# STM32H743 register map
File version: 2.4
CPU: CM7 r0p1, little endian, MPU, FPU, 4 interrupt priority bits
Registers are 32-bit, read-write, reset 0x0 unless marked. A register's access mark holds for its fields unless they carry their own. Offsets are from the block's base; [hi:lo] are bit positions.

## CEC — HDMI-CEC 控制器
Base 0x40006C00
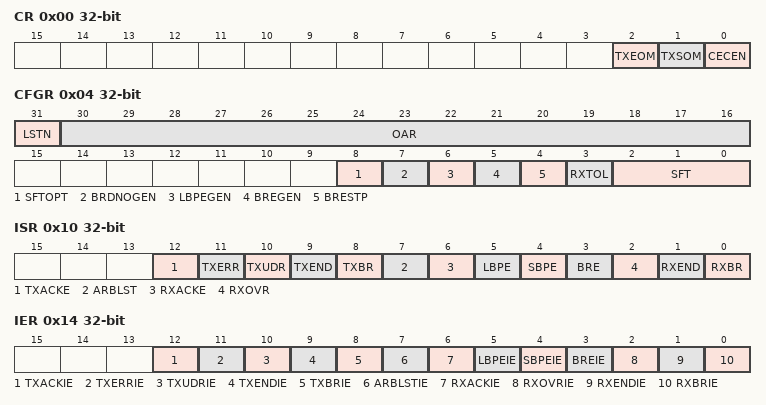
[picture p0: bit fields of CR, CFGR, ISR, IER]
0x00 CR — CEC 控制寄存器
  [2] TXEOM — 发送消息结束 TXEOM 由软件置位，用于命令发送 CEC 消息的最后一个字节。TXEOM 在与 TXSOM 相同的时间和条件下由硬件清零。注意：TXEOM 必须在 CECEN=1 时置位；TXEOM 必须在向 TXDR 写入发送数据之前置位；若 TXEOM 在 TXSOM=0 时置位，发送的消息将仅包含 1 个字节（HEADER）（即 PING 消息）。
  [1] TXSOM — 发送消息起始 TXSOM 由软件置位，用于命令发送 CEC 消息的第一个字节。如果 CEC 消息仅包含一个字节，则 TXEOM 必须在 TXSOM 之前置位。起始位在 SFT 计数完成后于 CEC 线上实际开始。如果在消息接收进行中置位 TXSOM，发送将在接收结束后开始。TXSOM 在消息最后一个字节发送成功并收到正应答后（TXEND=1）、发生发送欠载（TXUDR=1）、收到负应答（TXACKE=1）以及发送错误（TXERR=1）时由硬件清零。CECEN=0 也会将其清零。在仲裁丢失（ARBLST=1）的情况下，TXSOM 不会被清零，发送将自动重试。TXSOM 也可作为状态位，用于通知应用程序当前是否有发送请求等待处理或正在执行。应用程序可随时通过清零 CECEN 位来中止发送请求。注意：TXSOM 必须在 CECEN=1 时置位；TXSOM 必须在 TXDR 中有发送数据可用时置位；HEADER 的前四位（包含本机外设地址）取自 TXDR[7:4]，而非 CEC_CFGR.OAR，后者仅用于接收。
  [0] CECEN — CEC 使能 CECEN 位由软件置位和清零。CECEN=1 启动消息接收并使能 TXSOM 控制。CECEN=0 禁用 CEC 外设，清零 CEC_CR 寄存器的所有位，并中止任何正在进行的接收或发送。
0x04 CFGR — 此寄存器用于配置 HDMI-CEC 控制器。必须仅在 CECEN=0 时才能写 CEC_CFGR。
  [31] LSTN — 侦听模式 LSTN 位由软件置位和清零。
  [30:16] OAR — 本机地址配置 OAR 位由软件置位，用于选择在接收模式下需要考虑的目标逻辑地址。每个位置位时，使能由该位位置标识的 CEC 逻辑地址。HEADER 接收结束时，将收到的目标地址与已使能的地址进行比较。若地址匹配，则应答并接收传入消息。若地址不匹配，则仅在侦听模式（LSTN=1）下接收传入消息，但不发送应答。广播消息始终被接收。示例：OAR = 0b000 0000 0010 0001 表示 CEC 应答地址 0x0 和 0x5。因此，发往这两个地址中任意一个的每条消息均会被接收。
  [8] SFTOPT — SFT 选项位 SFTOPT 位由软件置位和清零。
  [7] BRDNOGEN — 禁止广播中生成错误位 BRDNOGEN 位由软件置位和清零。
  [6] LBPEGEN — 长位周期错误时生成错误位 LBPEGEN 位由软件置位和清零。注意：若 BRDNOGEN=0，在广播中检测到 LBPE 时，即使 LBPEGEN=0 也会生成错误位。
  [5] BREGEN — 位上升沿错误时生成错误位 BREGEN 位由软件置位和清零。注意：若 BRDNOGEN=0，在广播中检测到 BRE 且 BRESTP=1 时，即使 BREGEN=0 也会生成错误位。
  [4] BRESTP — 位上升沿错误时停止接收 BRESTP 位由软件置位和清零。
  [3] RXTOL — 接收容差 RXTOL 位由软件置位和清零。** 标准容差：起始位上升沿 +/- 200μs，下降沿 +/- 200μs；数据位上升沿 +/- 200μs，下降沿 +/- 350μs。** 扩展容差：起始位上升沿 +/- 400μs，下降沿 +/- 400μs；数据位上升沿 +/- 300μs，下降沿 +/- 500μs。
  [2:0] SFT — 信号空闲时间 SFT 位由软件置位。在 SFT=0x0 配置下，发送前等待的标称数据位周期数由硬件根据发送历史决定。在所有其他配置下，SFT 数值由软件确定。* 0x0：** 若 CEC 是上次总线发起者且发送不成功（ARBLST=1、TXERR=1、TXUDR=1 或 TXACKE=1），则等待 2.5 个数据位周期；** 若 CEC 是新的总线发起者，则等待 4 个数据位周期；** 若 CEC 是上次总线发起者且发送成功（TXEOM=1），则等待 6 个数据位周期；* 0x1：0.5 个标称数据位周期 * 0x2：1.5 个标称数据位周期 * 0x3：2.5 个标称数据位周期 * 0x4：3.5 个标称数据位周期 * 0x5：4.5 个标称数据位周期 * 0x6：5.5 个标称数据位周期 * 0x7：6.5 个标称数据位周期
0x08 TXDR wo — CEC 发送数据寄存器
  [7:0] TXD — 发送数据寄存器。TXD 为只写寄存器，包含待发送的数据字节。注意：TXD 必须在 TXSTART=1 时写入。
0x0C RXDR ro — CEC 接收数据寄存器
  [7:0] RXD — 接收数据寄存器。RXD 为只读寄存器，包含从 CEC 线上收到的最后一个数据字节。
0x10 ISR — CEC 中断和状态寄存器
  [12] TXACKE — 发送应答丢失错误 在发送模式下，TXACKE 由硬件置位，用于通知应用程序未收到应答。在广播发送情况下，TXACKE 通知应用程序收到了负应答。TXACKE 中止消息发送并清零 TXSOM 和 TXEOM 控制位。TXACKE 由软件写 1 清零。
  [11] TXERR — 发送错误 在发送模式下，若 CEC 发起者在释放 CEC 线时检测到低阻抗，TXERR 由硬件置位。TXERR 中止消息发送并清零 TXSOM 和 TXEOM 控制位。TXERR 由软件写 1 清零。
  [10] TXUDR — 发送缓冲区欠载 在发送模式下，若应用程序未能在下一字节发送前及时加载 TXDR，TXUDR 由硬件置位。TXUDR 中止消息发送并清零 TXSOM 和 TXEOM 控制位。TXUDR 由软件写 1 清零。
  [9] TXEND — 发送结束 TXEND 由硬件置位，用于通知应用程序 CEC 消息的最后一个字节已成功发送。TXEND 清零 TXSOM 和 TXEOM 控制位。TXEND 由软件写 1 清零。
  [8] TXBR — 发送字节请求 TXBR 由硬件置位，用于通知应用程序必须将下一个发送数据写入 TXDR。TXBR 在当前发送字节的第 4 位被发送时置位。应用程序必须在 6 个标称数据位周期内将下一个字节写入 TXDR，否则将发生发送欠载错误（TXUDR）。TXBR 由软件写 1 清零。
  [7] ARBLST — 仲裁丢失 ARBLST 由硬件置位，用于通知应用程序 CEC 设备因在 TXSOM 命令后发生仲裁丢失事件而切换到接收模式。ARBLST 可能由于另一个竞争 CEC 设备更早开始发送，或同时开始但具有更高 HEADER 优先级而导致。ARBLST 置位后，TXSOM 位保持等待状态，以备下次发送尝试。ARBLST 由软件写 1 清零。
  [6] RXACKE — 接收应答丢失 在接收模式下，RXACKE 由硬件置位，用于通知应用程序在 CEC 线上未检测到应答。RXACKE 仅适用于广播消息，以及在侦听模式下也适用于非直接寻址的消息（目标地址未在 OAR 中使能）。RXACKE 中止消息接收。RXACKE 由软件写 1 清零。
  [5] LBPE — 接收长位周期错误 当检测到数据位波形存在长位周期错误时，LBPE 由硬件置位。当下降沿仍未到来时，LBPE 在 RXTOL 允许的最大位周期扩展容差结束时置位。LBPE 始终停止 CEC 消息接收。若 LBPEGEN=1，则 LBPE 在 CEC 线上生成错误位。在广播情况下，即使 LBPEGEN=0 也会生成错误位。LBPE 由软件写 1 清零。
  [4] SBPE — 接收短位周期错误 当检测到数据位波形存在短位周期错误时，SBPE 由硬件置位。SBPE 在提前出现的下降沿发生时置位。SBPE 在 CEC 线上生成错误位。SBPE 由软件写 1 清零。
  [3] BRE — 接收位上升沿错误 当检测到数据位波形存在位上升沿错误时，BRE 由硬件置位。BRE 在错误位置的上升沿出现时置位，或当上升沿仍未到来时，在 RXTOL 允许的最大 BRE 容差结束时置位。若 BRESTP=1，则 BRE 停止消息接收。若 BREGEN=1，则 BRE 在 CEC 线上生成错误位。BRE 由软件写 1 清零。
  [2] RXOVR — 接收溢出 RXOVR 在新字节从 CEC 线收到并存入 RXD 时，若 RXBR 尚未清零，则由硬件置位。RXOVR 置位会停止消息接收，因此不发送应答。在广播情况下，发送负应答。RXOVR 由软件写 1 清零。
  [1] RXEND — 接收结束 RXEND 由硬件置位，用于通知应用程序 CEC 消息的最后一个字节已从 CEC 线收到并存入 RXD 缓冲区。RXEND 与 RXBR 同时置位。RXEND 由软件写 1 清零。
  [0] RXBR — 接收字节已收到 RXBR 由硬件置位，用于通知应用程序已从 CEC 线收到一个新字节并存入 RXD 缓冲区。RXBR 由软件写 1 清零。
0x14 IER — CEC 中断使能寄存器
  [12] TXACKIE — 发送应答丢失错误中断使能 TXACKEIE 位由软件置位和清零。
  [11] TXERRIE — 发送错误中断使能 TXERRIE 位由软件置位和清零。
  [10] TXUDRIE — 发送欠载中断使能 TXUDRIE 位由软件置位和清零。
  [9] TXENDIE — 发送消息结束中断使能 TXENDIE 位由软件置位和清零。
  [8] TXBRIE — 发送字节请求中断使能 TXBRIE 位由软件置位和清零。
  [7] ARBLSTIE — 仲裁丢失中断使能 ARBLSTIE 位由软件置位和清零。
  [6] RXACKIE — 接收应答丢失错误中断使能 RXACKIE 位由软件置位和清零。
  [5] LBPEIE — 长位周期错误中断使能 LBPEIE 位由软件置位和清零。
  [4] SBPEIE — 短位周期错误中断使能 SBPEIE 位由软件置位和清零。
  [3] BREIE — 位上升沿错误中断使能 BREIE 位由软件置位和清零。
  [2] RXOVRIE — 接收缓冲区溢出中断使能 RXOVRIE 位由软件置位和清零。
  [1] RXENDIE — 接收结束中断使能 RXENDIE 位由软件置位和清零。
  [0] RXBRIE — 接收字节已收到中断使能 RXBRIE 位由软件置位和清零。
